# G32R430xx register map
Vendor: Geehy Semiconductor Co., Ltd.; Series: G32R4; File version: 1.0
CPU: CM52 r0p1, little endian, MPU, no FPU, DSP, VTOR, 4 interrupt priority bits
Registers are 32-bit, read-write, reset 0x0 unless marked. A register's access mark holds for its fields unless they carry their own. Offsets are from the block's base; [hi:lo] are bit positions; {n}, {i} and the like mark numbered series.

## GPIO — General purpose I/O
Base 0x40021800
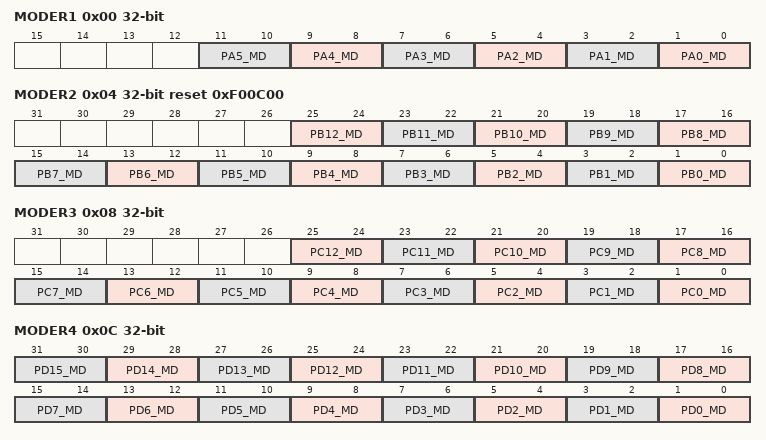
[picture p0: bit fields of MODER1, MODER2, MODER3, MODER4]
0x00 MODER1 — GPIO mode register 1
  [2n+1:2n] PA{n}_MD (n=0..5) — Work Mode Configuration
0x04 MODER2 reset 0xF00C00 — GPIO mode register 2
  [2n+1:2n] PB{n}_MD (n=0..12) — Work Mode Configuration
0x08 MODER3 — GPIO mode register 3
  [2n+1:2n] PC{n}_MD (n=0..12) — Work Mode Configuration
0x0C MODER4 — GPIO mode register 4
  [2n+1:2n] PD{n}_MD (n=0..15) — Work Mode Configuration
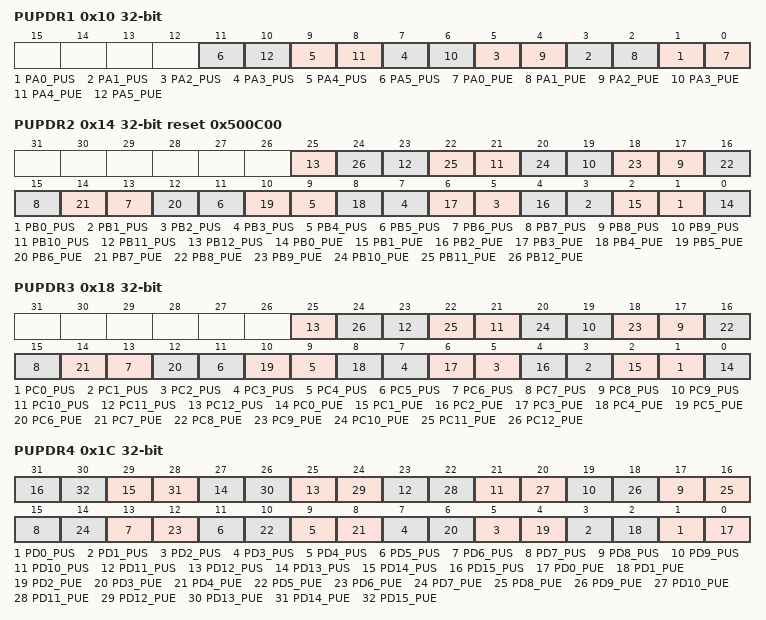
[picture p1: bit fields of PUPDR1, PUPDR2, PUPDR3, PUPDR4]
0x10 PUPDR1 — GPIO pull-up/pull-down register 1
  [2n+1] PA{n}_PUS (n=0..5) — Select from top to bottom (effective after enabling top-down selection)
  [2n] PA{n}_PUE (n=0..5) — PAD pull-up and pull-down enable
0x14 PUPDR2 reset 0x500C00 — GPIO pull-up/pull-down register 2
  [2n+1] PB{n}_PUS (n=0..12) — Select from top to bottom (effective after enabling top-down selection)
  [2n] PB{n}_PUE (n=0..12) — PAD pull-up and pull-down enable
0x18 PUPDR3 — GPIO pull-up/pull-down register 3
  [2n+1] PC{n}_PUS (n=0..12) — Select from top to bottom (effective after enabling top-down selection)
  [2n] PC{n}_PUE (n=0..12) — PAD pull-up and pull-down enable
0x1C PUPDR4 — GPIO pull-up/pull-down register 4
  [2n+1] PD{n}_PUS (n=0..15) — Select from top to bottom (effective after enabling top-down selection)
  [2n] PD{n}_PUE (n=0..15) — PAD pull-up and pull-down enable
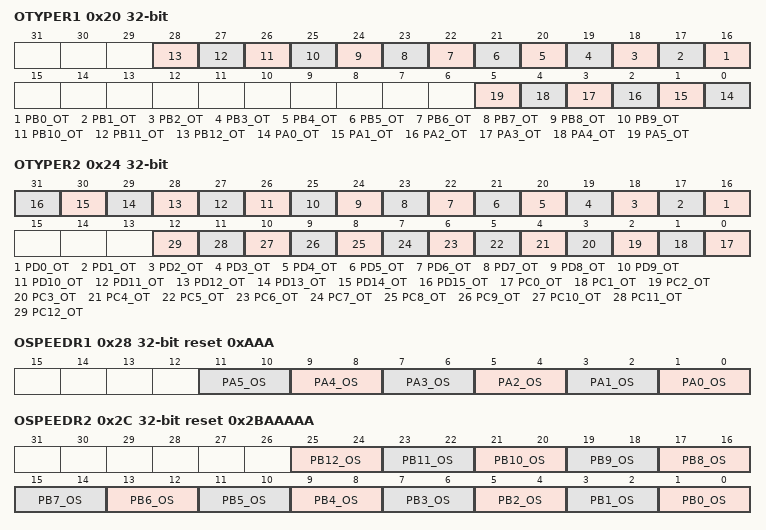
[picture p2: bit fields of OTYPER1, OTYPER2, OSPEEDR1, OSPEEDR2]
0x20 OTYPER1 — GPIO output type register 1
  [n+16] PB{n}_OT (n=0..12) — PAD output type configuration
  [n] PA{n}_OT (n=0..5) — PAD output type configuration
0x24 OTYPER2 — GPIO output type register 2
  [n+16] PD{n}_OT (n=0..15) — PAD output type configuration
  [n] PC{n}_OT (n=0..12) — PAD output type configuration
0x28 OSPEEDR1 reset 0xAAA — GPIO output speed register 1
  [2n+1:2n] PA{n}_OS (n=0..5) — PAD output speed configuration
0x2C OSPEEDR2 reset 0x2BAAAAA — GPIO output speed register 2
  [2n+1:2n] PB{n}_OS (n=0..12) — PAD output speed configuration
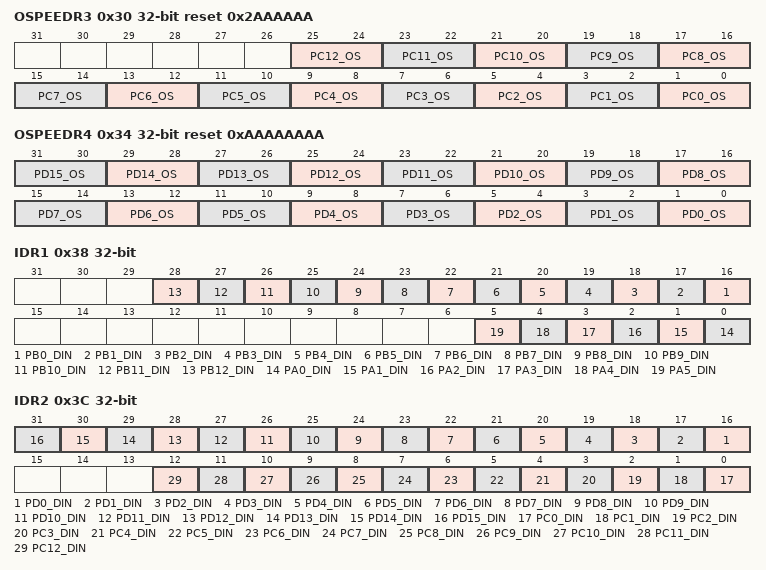
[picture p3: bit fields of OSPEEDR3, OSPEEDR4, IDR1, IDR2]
0x30 OSPEEDR3 reset 0x2AAAAAA — GPIO output speed register 3
  [2n+1:2n] PC{n}_OS (n=0..12) — PAD output speed configuration
0x34 OSPEEDR4 reset 0xAAAAAAAA — GPIO output speed register 4
  [2n+1:2n] PD{n}_OS (n=0..15) — PAD output speed configuration
0x38 IDR1 ro — GPIO input data register 1
  [n+16] PB{n}_DIN (n=0..12) — PAD input data
  [n] PA{n}_DIN (n=0..5) — PAD input data
0x3C IDR2 ro — GPIO input data register 2
  [n+16] PD{n}_DIN (n=0..15) — PAD input data
  [n] PC{n}_DIN (n=0..12) — PAD input data
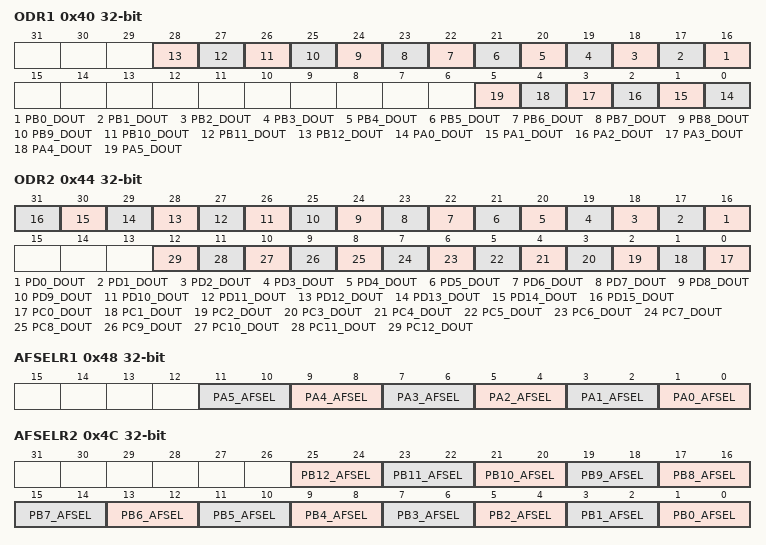
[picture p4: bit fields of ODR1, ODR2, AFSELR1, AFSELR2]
0x40 ODR1 — GPIO output data register 1
  [n+16] PB{n}_DOUT (n=0..12) — PAD output data
  [n] PA{n}_DOUT (n=0..5) — PAD output data
0x44 ODR2 — GPIO output data register 2
  [n+16] PD{n}_DOUT (n=0..15) — PAD output data
  [n] PC{n}_DOUT (n=0..12) — PAD output data
0x48 AFSELR1 — GPIO alternate function register 1
  [2n+1:2n] PA{n}_AFSEL (n=0..5) — PAD reuse selection
0x4C AFSELR2 — GPIO alternate function register 2
  [2n+1:2n] PB{n}_AFSEL (n=0..12) — PAD reuse selection
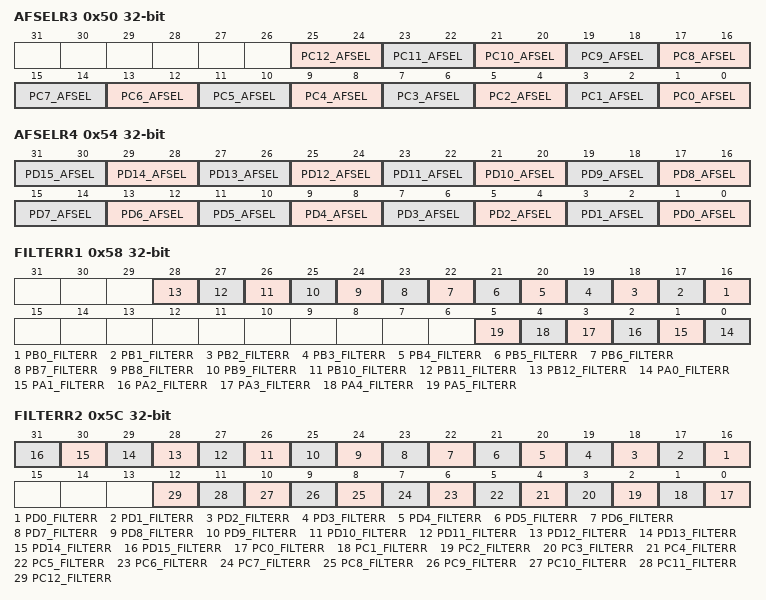
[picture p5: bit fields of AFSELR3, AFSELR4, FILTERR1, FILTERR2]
0x50 AFSELR3 — GPIO alternate function register 3
  [2n+1:2n] PC{n}_AFSEL (n=0..12) — PAD reuse selection
0x54 AFSELR4 — GPIO alternate function register 4
  [2n+1:2n] PD{n}_AFSEL (n=0..15) — PAD reuse selection
0x58 FILTERR1 — Wave Filter Enable Register 1
  [n+16] PB{n}_FILTERR (n=0..12) — PAD Filtering selection
  [n] PA{n}_FILTERR (n=0..5) — PAD Filtering selection
0x5C FILTERR2 — Wave Filter Enable Register 2
  [n+16] PD{n}_FILTERR (n=0..15) — PAD Filtering selection
  [n] PC{n}_FILTERR (n=0..12) — PAD Filtering selection
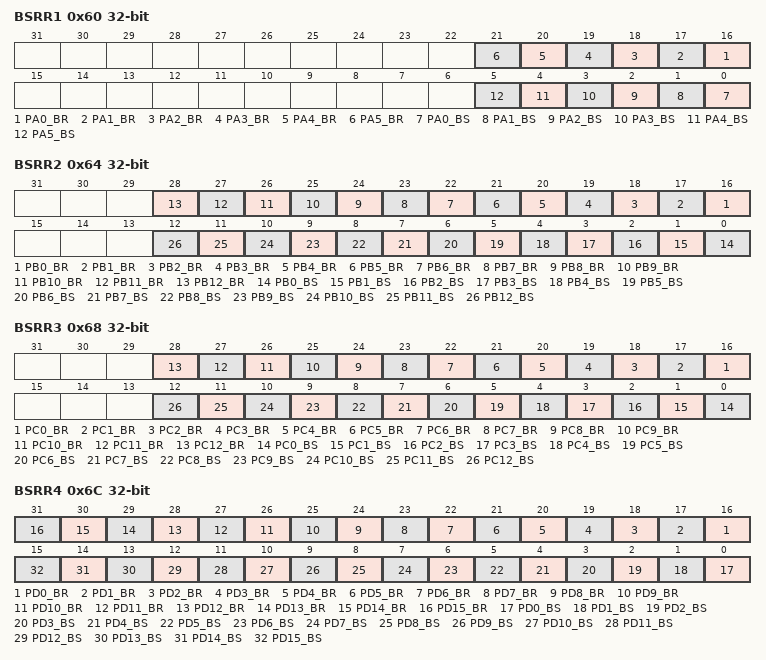
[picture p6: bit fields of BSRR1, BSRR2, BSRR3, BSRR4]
0x60 BSRR1 — Bit Set/Reset Register 1
  [n+16] PA{n}_BR (n=0..5) — PAD reset pin
  [n] PA{n}_BS (n=0..5) — PAD set pin
0x64 BSRR2 — Bit Set/Reset Register 2
  [n+16] PB{n}_BR (n=0..12) — PAD reset pin
  [n] PB{n}_BS (n=0..12) — PAD set pin
0x68 BSRR3 — Bit Set/Reset Register 3
  [n+16] PC{n}_BR (n=0..12) — PAD reset pin
  [n] PC{n}_BS (n=0..12) — PAD set pin
0x6C BSRR4 — Bit Set/Reset Register 4
  [n+16] PD{n}_BR (n=0..15) — PAD reset pin
  [n] PD{n}_BS (n=0..15) — PAD set pin
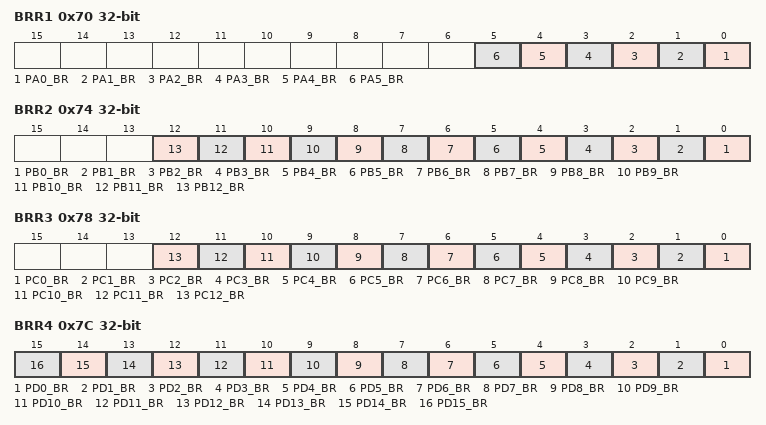
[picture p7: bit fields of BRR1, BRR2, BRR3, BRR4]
0x70 BRR1 — Bit Reset Register 1
  [n] PA{n}_BR (n=0..5) — PAD reset pin
0x74 BRR2 — Bit Reset Register 2
  [n] PB{n}_BR (n=0..12) — PAD reset pin
0x78 BRR3 — Bit Reset Register 3
  [n] PC{n}_BR (n=0..12) — PAD reset pin
0x7C BRR4 — Bit Reset Register 4
  [n] PD{n}_BR (n=0..15) — PAD reset pin
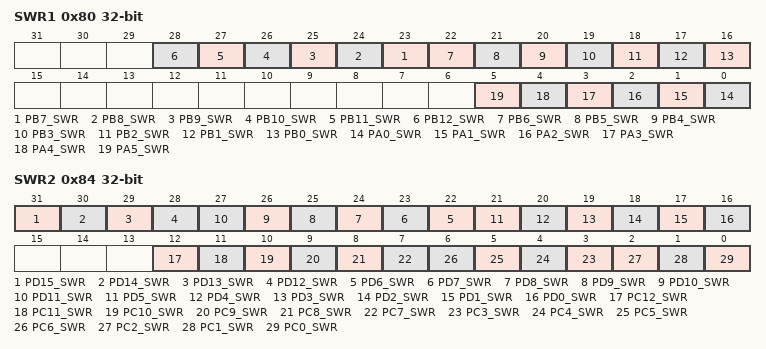
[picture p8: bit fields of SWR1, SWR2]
0x80 SWR1 — GPIO analog switch register 1 (PA0-PA5, PB0-PB12). Set a bit only for listed ADC3 channels or 5VIO pins (PB4, PB6, …); otherwise keep 0. Do not enable for ADC16 GPIO.
  [n+16] PB{n}_SWR (n=7..12) — Reserved for analog switch. Keep 0. Setting 1 can short internal analog paths (e.g. PA2 with PA5). Do not enable for ADC16 GPIO.
  [22] PB6_SWR — Special pin type: 0 = digital 5 V-tolerant input, 1 = analog 3.3 V input/output. Set 1 only when the pin is used as analog 3.3 V I/O.
  [21] PB5_SWR — Enable ADC3 analog switch. Set only when the pin is used as the listed ADC3 channel; otherwise keep 0 to avoid internal analog short.
  [20] PB4_SWR — Special pin type: 0 = digital 5 V-tolerant input, 1 = analog 3.3 V input/output. Set 1 only when the pin is used as analog 3.3 V I/O.
  [19] PB3_SWR — Enable ADC3 analog switch. Set only when the pin is used as the listed ADC3 channel; otherwise keep 0 to avoid internal analog short.
  [18] PB2_SWR — Enable ADC3 analog switch. Set only when the pin is used as the listed ADC3 channel; otherwise keep 0 to avoid internal analog short.
  [17] PB1_SWR — Reserved for analog switch. Keep 0. Setting 1 can short internal analog paths (e.g. PA2 with PA5). Do not enable for ADC16 GPIO.
  [16] PB0_SWR — Reserved for analog switch. Keep 0. Setting 1 can short internal analog paths (e.g. PA2 with PA5). Do not enable for ADC16 GPIO.
  [n] PA{n}_SWR (n=0..5) — Reserved for analog switch. Keep 0. Setting 1 can short internal analog paths (e.g. PA2 with PA5). Do not enable for ADC16 GPIO.
0x84 SWR2 — GPIO analog switch register 2 (PC0-PC12, PD0-PD15). Set a bit only for listed ADC3 channels or 5VIO pins (PC12, PD5, PD12); otherwise keep 0. PD15 is not in the 5VIO table; for EVS keep 0 (recommended). Do not enable for ADC16 GPIO.
  [31] PD15_SWR — PD15 is not in the 5VIO SWR=1 table. For EVS keep 0 (recommended). SWR=1 is not recommended; EVS still functions with SWR=1.
  [30] PD14_SWR — Reserved for analog switch. Keep 0. Setting 1 can short internal analog paths (e.g. PA2 with PA5). Do not enable for ADC16 GPIO.
  [29] PD13_SWR — Reserved for analog switch. Keep 0. Setting 1 can short internal analog paths (e.g. PA2 with PA5). Do not enable for ADC16 GPIO.
  [28] PD12_SWR — Special pin type: 0 = digital 5 V-tolerant input, 1 = analog 3.3 V input/output. Set 1 only when the pin is used as analog 3.3 V I/O.
  [n+16] PD{n}_SWR (n=6..11) — Reserved for analog switch. Keep 0. Setting 1 can short internal analog paths (e.g. PA2 with PA5). Do not enable for ADC16 GPIO.
  [21] PD5_SWR — Special pin type: 0 = digital 5 V-tolerant input, 1 = analog 3.3 V input/output. Set 1 only when the pin is used as analog 3.3 V I/O.
  [20] PD4_SWR — Reserved for analog switch. Keep 0. Setting 1 can short internal analog paths (e.g. PA2 with PA5). Do not enable for ADC16 GPIO.
  [19] PD3_SWR — Reserved for analog switch. Keep 0. Setting 1 can short internal analog paths (e.g. PA2 with PA5). Do not enable for ADC16 GPIO.
  [18] PD2_SWR — Enable ADC3 analog switch. Set only when the pin is used as the listed ADC3 channel; otherwise keep 0 to avoid internal analog short.
  [17] PD1_SWR — Enable ADC3 analog switch. Set only when the pin is used as the listed ADC3 channel; otherwise keep 0 to avoid internal analog short.
  [16] PD0_SWR — Enable ADC3 analog switch. Set only when the pin is used as the listed ADC3 channel; otherwise keep 0 to avoid internal analog short.
  [12] PC12_SWR — Special pin type: 0 = digital 5 V-tolerant input, 1 = analog 3.3 V input/output. Set 1 only when the pin is used as analog 3.3 V I/O.
  [11] PC11_SWR — Enable ADC3 analog switch. Set only when the pin is used as the listed ADC3 channel; otherwise keep 0 to avoid internal analog short.
  [10] PC10_SWR — Enable ADC3 analog switch. Set only when the pin is used as the listed ADC3 channel; otherwise keep 0 to avoid internal analog short.
  [9] PC9_SWR — Enable ADC3 analog switch. Set only when the pin is used as the listed ADC3 channel; otherwise keep 0 to avoid internal analog short.
  [8] PC8_SWR — Reserved for analog switch. Keep 0. Setting 1 can short internal analog paths (e.g. PA2 with PA5). Do not enable for ADC16 GPIO.
  [7] PC7_SWR — Reserved for analog switch. Keep 0. Setting 1 can short internal analog paths (e.g. PA2 with PA5). Do not enable for ADC16 GPIO.
  [n] PC{n}_SWR (n=3..6) — Enable ADC3 analog switch. Set only when the pin is used as the listed ADC3 channel; otherwise keep 0 to avoid internal analog short.
  [2] PC2_SWR — Reserved for analog switch. Keep 0. Setting 1 can short internal analog paths (e.g. PA2 with PA5). Do not enable for ADC16 GPIO.
  [1] PC1_SWR — Reserved for analog switch. Keep 0. Setting 1 can short internal analog paths (e.g. PA2 with PA5). Do not enable for ADC16 GPIO.
  [0] PC0_SWR — Reserved for analog switch. Keep 0. Setting 1 can short internal analog paths (e.g. PA2 with PA5). Do not enable for ADC16 GPIO.
